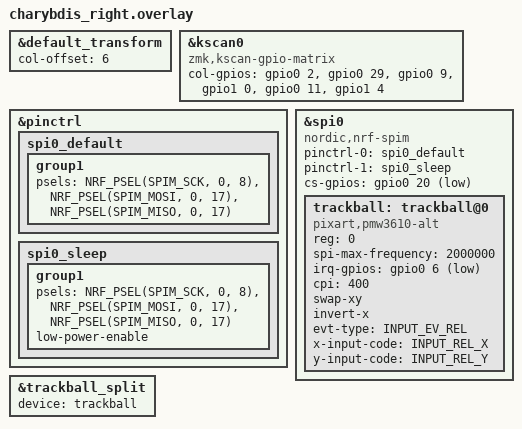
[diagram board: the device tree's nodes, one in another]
/*
 * Copyright (c) 2020 ZMK Contributors
 *
 * SPDX-License-Identifier: MIT
 */

#include "charybdis.dtsi"
#include <zephyr/dt-bindings/input/input-event-codes.h>

&default_transform {
    col-offset = <6>;
};

&kscan0 {
	compatible = "zmk,kscan-gpio-matrix";

	col-gpios
		= <&gpio0 2 (GPIO_ACTIVE_HIGH | GPIO_PULL_DOWN)>
		, <&gpio0 29 (GPIO_ACTIVE_HIGH | GPIO_PULL_DOWN)>
		, <&gpio0 9 (GPIO_ACTIVE_HIGH | GPIO_PULL_DOWN)>
		, <&gpio1 0  (GPIO_ACTIVE_HIGH | GPIO_PULL_DOWN)>
		, <&gpio0 11 (GPIO_ACTIVE_HIGH | GPIO_PULL_DOWN)>
		, <&gpio1 4  (GPIO_ACTIVE_HIGH | GPIO_PULL_DOWN)>
		;
};

// trackball bus
&pinctrl {
    spi0_default: spi0_default {
        group1 {
            psels = <NRF_PSEL(SPIM_SCK, 0, 8)>,
                <NRF_PSEL(SPIM_MOSI, 0, 17)>,
                <NRF_PSEL(SPIM_MISO, 0, 17)>;
        };
    };

    spi0_sleep: spi0_sleep {
        group1 {
            psels = <NRF_PSEL(SPIM_SCK, 0, 8)>,
                <NRF_PSEL(SPIM_MOSI, 0, 17)>,
                <NRF_PSEL(SPIM_MISO, 0, 17)>;
            low-power-enable;
        };
    };
};

&spi0 {
    status = "okay";
    compatible = "nordic,nrf-spim";
    pinctrl-0 = <&spi0_default>;
    pinctrl-1 = <&spi0_sleep>;
    pinctrl-names = "default", "sleep";
    cs-gpios = <&gpio0 20 GPIO_ACTIVE_LOW>;

    trackball: trackball@0 {
        status = "okay";
        compatible = "pixart,pmw3610-alt";
        reg = <0>;
        spi-max-frequency = <2000000>;
        irq-gpios = <&gpio0 6 (GPIO_ACTIVE_LOW | GPIO_PULL_UP)>;

        cpi = <400>;
        // Orientation: replaces the old CONFIG_PMW3610_ORIENTATION_90 +
        // CONFIG_PMW3610_INVERT_X. Tweak swap-xy / invert-x / invert-y if the
        // cursor moves along the wrong axis or in the wrong direction.
        swap-xy;
        invert-x;

        evt-type = <INPUT_EV_REL>;
        x-input-code = <INPUT_REL_X>;
        y-input-code = <INPUT_REL_Y>;
    };
};

// Forward the local trackball's motion to the central (dongle) over the split.
&trackball_split {
    device = <&trackball>;
};
